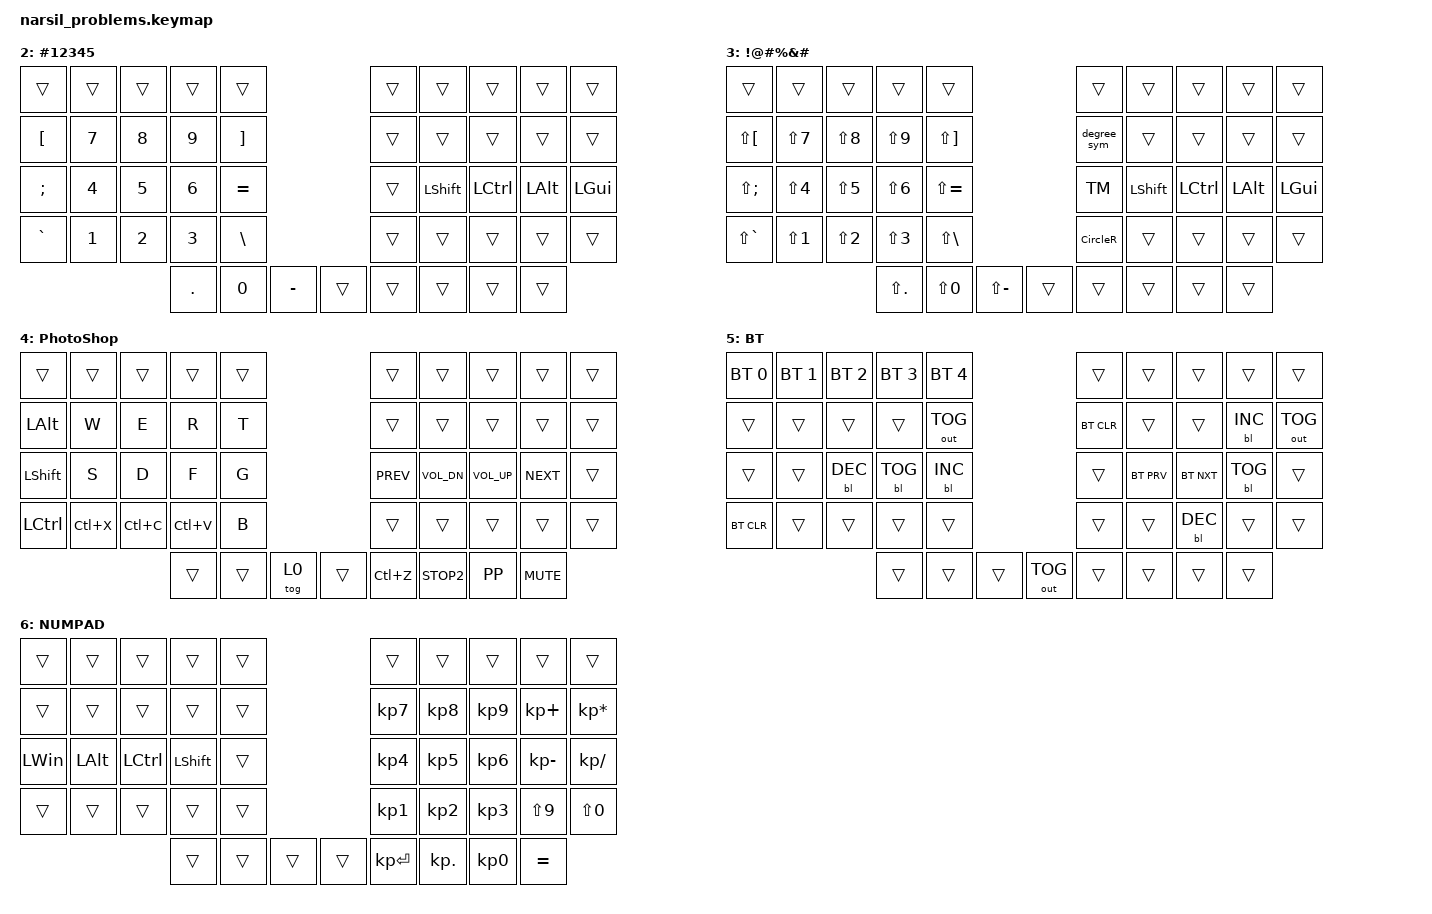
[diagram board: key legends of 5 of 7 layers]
#include <behaviors.dtsi>
#include <dt-bindings/zmk/keys.h>
#include <dt-bindings/zmk/bt.h>
#include <dt-bindings/zmk/backlight.h>
#include <dt-bindings/zmk/outputs.h>
#include <dt-bindings/zmk/keys.h>


#define BASE 0
#define NAV  1
#define NUM  2
#define FUN  3
#define SYM  4
#define PS   5
#define BLU  6
#define PAD  7


&mt {
    quick-tap-ms = <100>;
    global-quick-tap;
    flavor = "tap-preferred";
    tapping-term-ms = <180>;
};


/ {
    macros {
        degree_sym: degree_sym {
            label = "Degree_symbol";
            compatible = "zmk,behavior-macro";
            #binding-cells = <0>;
            bindings =
                <&macro_tap_time 40>,
                <&macro_wait_time 40>,
                <&macro_press>,
                <&kp RALT>,
                <&macro_tap>,
                <&kp N2 &kp N4 &kp N8>,
                <&macro_pause_for_release>,
                <&macro_release>;

            tap-ms = <40>;
            wait-ms = <40>;
        };
        C_A_D: C_A_D {
            compatible = "zmk,behavior-macro";
            label = "Control Alt Delete";
            #binding-cells = <0>;
            bindings =
                <&macro_tap>,
                <&kp LA(LC(DEL))>,
                <&macro_pause_for_release>,
                <&macro_release>;

            tap-ms = <100>;
            wait-ms = <100>;
        };
        TM: TM {
            compatible = "zmk,behavior-macro";
            label = "TradeMark";
            #binding-cells = <0>;
            bindings =
                <&macro_press>,
                <&kp RALT>,
                <&macro_tap>,
                <&kp N0 &kp N1 &kp N5 &kp N3>,
                <&macro_pause_for_release>,
                <&macro_release>;

            tap-ms = <40>;
            wait-ms = <40>;
        };
        CircleR: CircleR {
            compatible = "zmk,behavior-macro";
            label = "CircleR";
            #binding-cells = <0>;
            bindings =
                <&macro_press>,
                <&kp RALT>,
                <&macro_tap>,
                <&kp KP_N1 &kp KP_N6 &kp KP_N9>,
                <&macro_release>,
                <&macro_release>;

            tap-ms = <40>;
            wait-ms = <40>;
        };
    };
};

/ {
    combos {
        compatible = "zmk,combos";

        combo_capslock {
            bindings = <&caps_word>;
            key-positions = <13 16>;
            layers = <0>;
        };
    };
};
/ {
    behaviors {
        pht: positional_hold_tap {
            compatible = "zmk,behavior-hold-tap";
            label = "POSITIONAL_HOLD_TAP";
            #binding-cells = <2>;
            flavor = "hold-preferred";
            tapping-term-ms = <400>;
            quick-tap-ms = <200>;
            bindings = <&kp>, <&kp>;
            hold-trigger-key-positions = <1>;    // <---[[the W key]]
        };
        gqt: global-quick-tap {
            compatible = "zmk,behavior-hold-tap";
            label = "GLOBAL_QUICK_TAP";
            #binding-cells = <2>;
            flavor = "tap-preferred";
            tapping-term-ms = <200>;
            quick-tap-ms = <125>;
            global-quick-tap;
            bindings = <&kp>, <&kp>;
        };
    };
    
    keymap {
        compatible = "zmk,keymap";

        default_layer {
        label = " QWERTY ";
            //          ------------------------------------------------------------------------------------------------------------
            //          |  1  |  2  |  3   |  4   |  5   |                                   |  6   |  7    |  8    |  9   |   0   |
            //          |  Q  |  W  |  E   |  R   |  T   |                                   |  Y   |  U    |  I    |  O   |   P   |
            //          |  A  |  S  |  D   |  F   |  G   |                                   |  H   |  J    |  K    |  L   |   '   |
            //          |  Z  |  X  |  C   |  V   |  B   | C/A/D|                    |  MUTE |  N   |  M    |  ,    |  .   |   /   |
            //                             | ESC  | SPC  |  TAB |                    |  RET  | BKSP |  DEL  |

            bindings = <
      &gqt LS(N1) N1 &gqt LS(N2) N2 &gqt LS(N3) N3 &gqt LS(N4) N4 &gqt LS(N5) N5                  &gqt LS(N6) N6   &gqt LS(N7)  N7 &gqt LS(N8) N8 &gqt LS(N9) N9 &gqt LS(N0) N0         
      &kp Q       &kp W        &kp E        &kp R        &kp T                                               &kp Y            &kp U        &kp I       &kp O  &gqt PSCRN P
      &kp A  &mt LALT S  &mt LCTRL D  &mt LSHFT F        &kp G                                               &kp H      &mt RSHFT J  &mt RCTRL K  &mt RALT L  &mt LGUI SQT
      &kp Z       &kp X        &kp C        &kp V        &kp B                                               &kp N            &kp M    &kp COMMA     &kp DOT      &kp FSLH
                                      &lt BLU ESC  &lt NAV SPACE  &lt PAD TAB &kp &C_A_D &kp C_MUTE &lt SYM RET  &lt NUM BSPC &lt PS DEL
            >;
            sensor-bindings = <&inc_dec_kp UP DOWN &inc_dec_kp C_VOL_DN C_VOL_UP>;
        };

        nav_layer {
            label = " NAV ";
            bindings = <
      &trans       &trans        &trans        &trans       &trans                                           &trans        &trans     &trans      &trans     &trans  
      &trans       &trans        &trans        &trans       &trans                                           &kp CAPS     &bt BT_NXT  &kp LC(X)   &kp LC(C)  &kp LC(V)
    &kp LGUI     &kp LALT     &kp LCTRL     &kp LSHFT       &trans                                           &kp LEFT      &kp DOWN     &kp UP   &kp RIGHT     &trans
   &kp LSHFT       &trans     &kp LC(L)        &trans       &C_A_D  &trans                                 &kp INSERT    &kp HOME  &kp PG_UP   &kp PG_DN    &kp END
                                            &kp LCTRL       &trans  &trans  &trans       &trans   &kp RET   &kp BSPC       &kp DEL
            >;
            sensor-bindings = <&inc_dec_kp UP DOWN &inc_dec_kp LEFT RIGHT>;
        };

        num_layer {
            label = " #12345 ";
            bindings = <
    &trans  &trans  &trans      &trans     &trans                                         &trans       &trans     &trans    &trans    &trans  
  &kp LBKT  &kp N7  &kp N8      &kp N9   &kp RBKT                                         &trans       &trans     &trans    &trans    &trans
  &kp SEMI  &kp N4  &kp N5      &kp N6  &kp EQUAL                                         &trans    &kp LSHFT  &kp LCTRL  &kp LALT  &kp LGUI
 &kp GRAVE  &kp N1  &kp N2      &kp N3   &kp BSLH                                         &trans       &trans     &trans    &trans    &trans
                            &kp PERIOD     &kp N0 &kp MINUS  &trans  &trans  &trans       &trans       &trans
            >;

            sensor-bindings = <&inc_dec_kp UP DOWN &inc_dec_kp C_VOL_DN C_VOL_UP>;
        };

        /*fun_layer {
            label = " FUNC ";
            bindings = <
  &trans  &trans  &trans   &trans           &trans                                       &trans       &trans     &trans    &trans      &trans  
 &kp F12  &kp F7  &kp F8   &kp F9           &sys_reset                               &sys_reset       &trans     &trans    &trans  &bl BL_INC
 &kp F11  &kp F4  &kp F5   &kp F6       &kp SYSREQ                                       &trans    &kp LSHFT  &kp LCTRL  &kp LALT  &bl BL_DEC
 &kp F10  &kp F1  &kp F2   &kp F3  &kp PAUSE_BREAK                                       &trans       &trans     &trans    &trans  &bl BL_TOG 
                          &kp ESC        &kp SPACE &kp TAB  &trans &trans    &trans      &trans       &trans
            >;

            sensor-bindings = <&inc_dec_kp UP DOWN &inc_dec_kp C_VOL_DN C_VOL_UP>;
        };*/

        sym_layer {
            label = " !@#%&# ";
            bindings = <
    &trans  &trans  &trans      &trans     &trans                                                                  &trans       &trans     &trans    &trans    &trans  
  &kp LS(LBKT)  &kp LS(N7)  &kp LS(N8)      &kp LS(N9)   &kp LS(RBKT)                                         &degree_sym       &trans     &trans    &trans    &trans
  &kp LS(SEMI)  &kp LS(N4)  &kp LS(N5)      &kp LS(N6)  &kp LS(EQUAL)                                                 &TM    &kp LSHFT  &kp LCTRL  &kp LALT  &kp LGUI
 &kp LS(GRAVE)  &kp LS(N1)  &kp LS(N2)      &kp LS(N3)   &kp LS(BSLH)                                            &CircleR       &trans     &trans    &trans    &trans
                                        &kp LS(PERIOD)     &kp LS(N0)  &kp LS(MINUS) &trans       &trans &trans    &trans       &trans
            >;

            sensor-bindings = <&inc_dec_kp UP DOWN &inc_dec_kp C_VOL_DN C_VOL_UP>;
        };

        PS_LAYER {
            label = " PhotoShop ";
            bindings = <    
      &trans     &trans       &trans        &trans       &trans                                                  &trans        &trans        &trans      &trans      &trans  
    &kp LALT      &kp W         &kp E        &kp R        &kp T                                                  &trans        &trans        &trans      &trans      &trans
   &kp LSHFT      &kp S         &kp D        &kp F        &kp G                                              &kp K_PREV  &kp K_VOL_DN  &kp K_VOL_UP  &kp K_NEXT      &trans
   &kp LCTRL  &kp LC(X)      &kp LC(C)    &kp LC(V)       &kp B                                                  &trans        &trans        &trans      &trans      &trans
                                             &trans      &trans    &tog 0  &trans   &kp LC(Z)  &kp K_STOP2       &kp K_PP    &kp K_MUTE
            >;
            sensor-bindings = <&inc_dec_kp  LBKT RBKT &inc_dec_kp LS(LBKT) LS(RBKT)>;
        };

        blu_layer {
            label = " BT";
            bindings = <
 &bt BT_SEL 0 &bt BT_SEL 1 &bt BT_SEL 2  &bt BT_SEL 3 &bt BT_SEL 4                                              &trans    &trans      &trans      &trans        &trans  
 &trans       &trans       &trans        &trans       &out OUT_TOG                                           &bt BT_CLR  &trans      &trans  &bl BL_INC  &out OUT_TOG
 &trans       &trans       &bl BL_DEC    &bl BL_TOG   &bl BL_INC                                                &trans  &bt BT_PRV  &bt BT_NXT  &bl BL_TOG      &trans
 &bt BT_CLR   &trans       &trans        &trans       &trans                                                    &trans      &trans  &bl BL_DEC  &trans          &trans
                                         &trans       &trans     &trans   &out OUT_TOG   &trans      &trans     &trans      &trans
            >;

            sensor-bindings = <&inc_dec_kp UP DOWN &inc_dec_kp C_VOL_DN C_VOL_UP>;
        };

        PAD_LAYER {
            label = " NUMPAD";
            bindings = <
   &trans    &trans     &trans     &trans  &trans                                                  &trans       &trans       &trans        &trans           &trans  
   &trans    &trans     &trans     &trans  &trans                                               &kp KP_N7     &kp KP_N8   &kp KP_N9   &kp KP_PLUS  &kp KP_MULTIPLY
 &kp LWIN  &kp LALT  &kp LCTRL  &kp LSHFT  &trans                                               &kp KP_N4     &kp KP_N5   &kp KP_N6  &kp KP_MINUS    &kp KP_DIVIDE
   &trans    &trans     &trans     &trans  &trans                                               &kp KP_N1     &kp KP_N2   &kp KP_N3    &kp LS(N9)       &kp LS(N0)
                                   &trans  &trans  &trans  &trans  &kp KP_ENTER  &kp KP_DOT     &kp KP_N0     &kp EQUAL
            >;

            sensor-bindings = <&inc_dec_kp UP DOWN &inc_dec_kp C_VOL_DN C_VOL_UP>;
        };
    };
};
